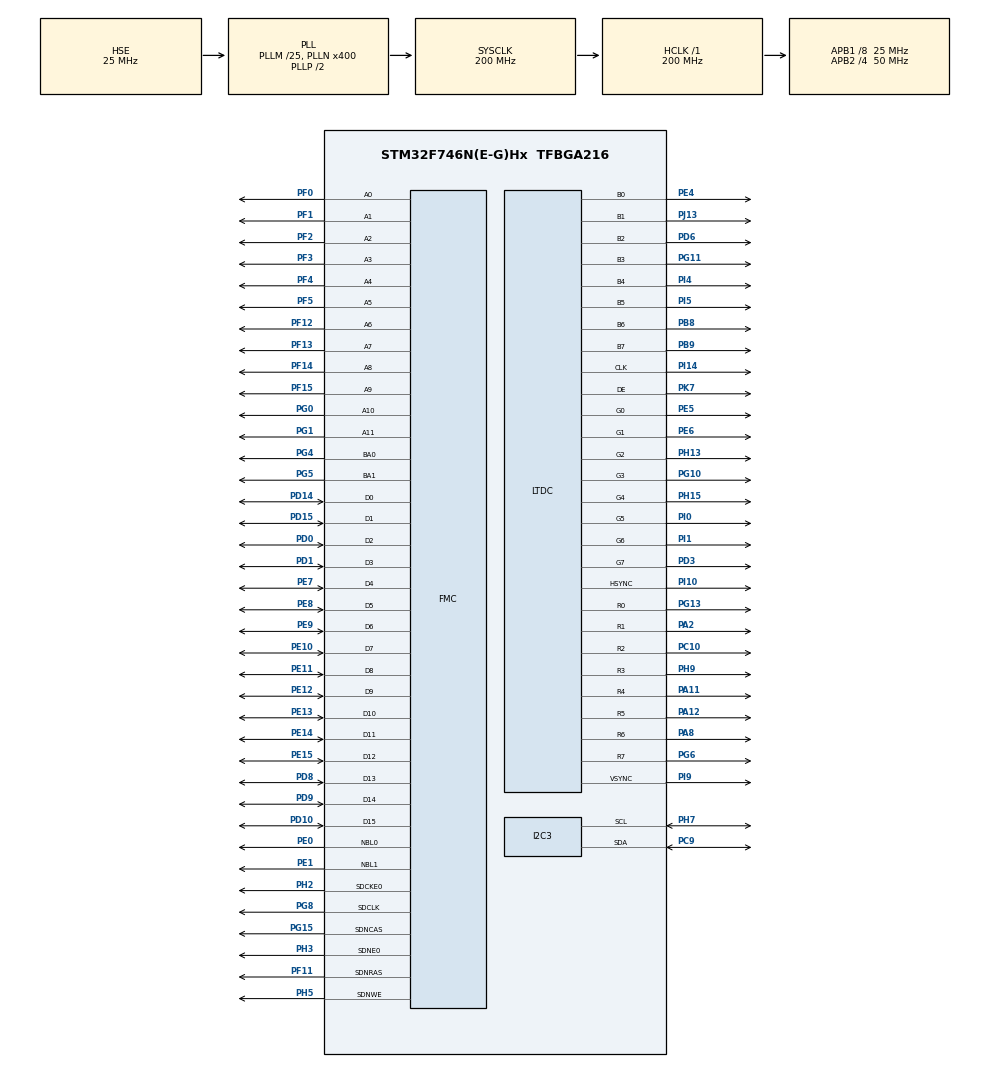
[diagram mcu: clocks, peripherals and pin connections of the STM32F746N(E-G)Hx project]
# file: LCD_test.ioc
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FMC.CASLatency1=FMC_SDRAM_CAS_LATENCY_2
FMC.ExitSelfRefreshDelay1=7
FMC.LoadToActiveDelay1=2
FMC.RCDDelay1=2
FMC.RPDelay1=2
FMC.RPDelay2=2
FMC.ReadBurst1=FMC_SDRAM_RBURST_ENABLE
FMC.ReadBurst2=FMC_SDRAM_RBURST_ENABLE
FMC.RowBitsNumber1=FMC_SDRAM_ROW_BITS_NUM_12
FMC.RowCycleDelay1=6
FMC.RowCycleDelay2=6
FMC.SDClockPeriod1=FMC_SDRAM_CLOCK_PERIOD_2
FMC.SDClockPeriod2=FMC_SDRAM_CLOCK_PERIOD_2
FMC.SelfRefreshTime1=4
FMC.WriteRecoveryTime1=2
I2C3.OwnAddress=112
I2C3.Timing=0x00606092
LTDC.ActiveH=272
LTDC.ActiveW=480
LTDC.HBP=43
LTDC.HFP=8
LTDC.HSync=1
LTDC.VBP=12
LTDC.VFP=4
LTDC.VSync=1
Mcu.Family=STM32F7
Mcu.Name=STM32F746N(E-G)Hx
Mcu.Package=TFBGA216
NVIC.PriorityGroup=NVIC_PRIORITYGROUP_4
PA11.Mode=RGB888
PA11.Signal=LTDC_R4
PA12.Mode=RGB888
PA12.Signal=LTDC_R5
PA2.Mode=RGB888
PA2.Signal=LTDC_R1
PA8.Mode=RGB888
PA8.Signal=LTDC_R6
PB8.Mode=RGB888
PB8.Signal=LTDC_B6
PB9.Mode=RGB888
PB9.Signal=LTDC_B7
PC10.Mode=RGB888
PC10.Signal=LTDC_R2
PC14/OSC32_IN.Mode=LSE-External-Oscillator
PC14/OSC32_IN.Signal=RCC_OSC32_IN
PC15/OSC32_OUT.Mode=LSE-External-Oscillator
PC15/OSC32_OUT.Signal=RCC_OSC32_OUT
PC9.Mode=I2C
PC9.Signal=I2C3_SDA
PD0.Signal=FMC_D2_DA2
PD1.Signal=FMC_D3_DA3
PD10.Signal=FMC_D15_DA15
PD14.Signal=FMC_D0_DA0
PD15.Signal=FMC_D1_DA1
PD3.Mode=RGB888
PD3.Signal=LTDC_G7
PD6.Mode=RGB888
PD6.Signal=LTDC_B2
PD8.Signal=FMC_D13_DA13
PD9.Signal=FMC_D14_DA14
PE0.Signal=FMC_NBL0
PE1.Signal=FMC_NBL1
PE10.Signal=FMC_D7_DA7
PE11.Signal=FMC_D8_DA8
PE12.Signal=FMC_D9_DA9
PE13.Signal=FMC_D10_DA10
PE14.Signal=FMC_D11_DA11
PE15.Signal=FMC_D12_DA12
PE4.Mode=RGB888
PE4.Signal=LTDC_B0
PE5.Mode=RGB888
PE5.Signal=LTDC_G0
PE6.Mode=RGB888
PE6.Signal=LTDC_G1
PE7.Signal=FMC_D4_DA4
PE8.Signal=FMC_D5_DA5
PE9.Signal=FMC_D6_DA6
PF0.Signal=FMC_A0
PF1.Signal=FMC_A1
PF11.Signal=FMC_SDNRAS
PF12.Signal=FMC_A6
PF13.Signal=FMC_A7
PF14.Signal=FMC_A8
PF15.Signal=FMC_A9
PF2.Signal=FMC_A2
PF3.Signal=FMC_A3
PF4.Signal=FMC_A4
PF5.Signal=FMC_A5
PG0.Signal=FMC_A10
PG1.Signal=FMC_A11
PG10.Mode=RGB888
PG10.Signal=LTDC_G3
PG11.Mode=RGB888
PG11.Signal=LTDC_B3
PG13.Mode=RGB888
PG13.Signal=LTDC_R0
PG15.Signal=FMC_SDNCAS
PG4.Signal=FMC_A14_BA0
PG5.Signal=FMC_A15_BA1
PG6.Mode=RGB888
PG6.Signal=LTDC_R7
PG8.Signal=FMC_SDCLK
PH0/OSC_IN.Mode=HSE-External-Oscillator
PH0/OSC_IN.Signal=RCC_OSC_IN
PH1/OSC_OUT.Mode=HSE-External-Oscillator
PH1/OSC_OUT.Signal=RCC_OSC_OUT
PH13.Mode=RGB888
PH13.Signal=LTDC_G2
PH15.Mode=RGB888
PH15.Signal=LTDC_G4
PH2.Mode=SdramChipSelect1_1
PH2.Signal=FMC_SDCKE0
PH3.Mode=SdramChipSelect1_1
PH3.Signal=FMC_SDNE0
PH5.Signal=FMC_SDNWE
PH7.Mode=I2C
PH7.Signal=I2C3_SCL
PH9.Mode=RGB888
PH9.Signal=LTDC_R3
PI0.Mode=RGB888
PI0.Signal=LTDC_G5
PI1.Mode=RGB888
PI1.Signal=LTDC_G6
PI10.Mode=RGB888
PI10.Signal=LTDC_HSYNC
PI14.Mode=RGB888
PI14.Signal=LTDC_CLK
PI4.Mode=RGB888
PI4.Signal=LTDC_B4
PI5.Mode=RGB888
PI5.Signal=LTDC_B5
PI9.Mode=RGB888
PI9.Signal=LTDC_VSYNC
PJ13.Mode=RGB888
PJ13.Signal=LTDC_B1
PK7.Mode=RGB888
PK7.Signal=LTDC_DE
ProjectManager.HeapSize=0x200
ProjectManager.StackSize=0x400
ProjectManager.TargetToolchain=SW4STM32
RCC.AHBFreq_Value=200000000
RCC.APB1CLKDivider=RCC_HCLK_DIV8
RCC.APB1Freq_Value=25000000
RCC.APB1TimFreq_Value=50000000
RCC.APB2CLKDivider=RCC_HCLK_DIV4
RCC.APB2Freq_Value=50000000
RCC.APB2TimFreq_Value=100000000
RCC.CortexFreq_Value=200000000
RCC.HCLKFreq_Value=200000000
RCC.HSE_VALUE=25000000
RCC.HSI_VALUE=16000000
RCC.PLLI2SN=100
RCC.PLLM=25
RCC.PLLN=400
RCC.PLLSAIR=5
RCC.PLLSAIRDiv=RCC_PLLSAIDIVR_4
RCC.PLLSourceVirtual=RCC_PLLSOURCE_HSE
RCC.SYSCLKFreq_VALUE=200000000
RCC.SYSCLKSource=RCC_SYSCLKSOURCE_PLLCLK
RCC.USBFreq_Value=200000000
RCC.VCOOutputFreq_Value=400000000
SH.FMC_A0.0=FMC_A0,12b-sda1
SH.FMC_A1.0=FMC_A1,12b-sda1
SH.FMC_A10.0=FMC_A10,12b-sda1
SH.FMC_A11.0=FMC_A11,12b-sda1
SH.FMC_A14_BA0.0=FMC_BA0,FourSdramBanks1
SH.FMC_A15_BA1.0=FMC_BA1,FourSdramBanks1
SH.FMC_A2.0=FMC_A2,12b-sda1
SH.FMC_A3.0=FMC_A3,12b-sda1
SH.FMC_A4.0=FMC_A4,12b-sda1
SH.FMC_A5.0=FMC_A5,12b-sda1
SH.FMC_A6.0=FMC_A6,12b-sda1
SH.FMC_A7.0=FMC_A7,12b-sda1
SH.FMC_A8.0=FMC_A8,12b-sda1
SH.FMC_A9.0=FMC_A9,12b-sda1
SH.FMC_D0_DA0.0=FMC_D0,sd-16b-d1
SH.FMC_D10_DA10.0=FMC_D10,sd-16b-d1
SH.FMC_D11_DA11.0=FMC_D11,sd-16b-d1
SH.FMC_D12_DA12.0=FMC_D12,sd-16b-d1
SH.FMC_D13_DA13.0=FMC_D13,sd-16b-d1
SH.FMC_D14_DA14.0=FMC_D14,sd-16b-d1
SH.FMC_D15_DA15.0=FMC_D15,sd-16b-d1
SH.FMC_D1_DA1.0=FMC_D1,sd-16b-d1
SH.FMC_D2_DA2.0=FMC_D2,sd-16b-d1
SH.FMC_D3_DA3.0=FMC_D3,sd-16b-d1
SH.FMC_D4_DA4.0=FMC_D4,sd-16b-d1
SH.FMC_D5_DA5.0=FMC_D5,sd-16b-d1
SH.FMC_D6_DA6.0=FMC_D6,sd-16b-d1
SH.FMC_D7_DA7.0=FMC_D7,sd-16b-d1
SH.FMC_D8_DA8.0=FMC_D8,sd-16b-d1
SH.FMC_D9_DA9.0=FMC_D9,sd-16b-d1
SH.FMC_NBL0.0=FMC_NBL0,Sd2ByteEnable1
SH.FMC_NBL1.0=FMC_NBL1,Sd2ByteEnable1
SH.FMC_SDCLK.0=FMC_SDCLK,12b-sda1
SH.FMC_SDNCAS.0=FMC_SDNCAS,12b-sda1
SH.FMC_SDNRAS.0=FMC_SDNRAS,12b-sda1
SH.FMC_SDNWE.0=FMC_SDNWE,12b-sda1
VP_DMA2D_VS_DMA2D.Mode=DMA2D_Activate
board=STM32F746G-DISCO

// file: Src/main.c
/**
  ******************************************************************************
  * File Name          : main.c
  * Description        : Main program body
  ******************************************************************************
  *
  * COPYRIGHT(c) 2016 STMicroelectronics
  *
  * Redistribution and use in source and binary forms, with or without modification,
  * are permitted provided that the following conditions are met:
  *   1. Redistributions of source code must retain the above copyright notice,
  *      this list of conditions and the following disclaimer.
  *   2. Redistributions in binary form must reproduce the above copyright notice,
  *      this list of conditions and the following disclaimer in the documentation
  *      and/or other materials provided with the distribution.
  *   3. Neither the name of STMicroelectronics nor the names of its contributors
  *      may be used to endorse or promote products derived from this software
  *      without specific prior written permission.
  *
  * THIS SOFTWARE IS PROVIDED BY THE COPYRIGHT HOLDERS AND CONTRIBUTORS "AS IS"
  * AND ANY EXPRESS OR IMPLIED WARRANTIES, INCLUDING, BUT NOT LIMITED TO, THE
  * IMPLIED WARRANTIES OF MERCHANTABILITY AND FITNESS FOR A PARTICULAR PURPOSE ARE
  * DISCLAIMED. IN NO EVENT SHALL THE COPYRIGHT HOLDER OR CONTRIBUTORS BE LIABLE
  * FOR ANY DIRECT, INDIRECT, INCIDENTAL, SPECIAL, EXEMPLARY, OR CONSEQUENTIAL
  * DAMAGES (INCLUDING, BUT NOT LIMITED TO, PROCUREMENT OF SUBSTITUTE GOODS OR
  * SERVICES; LOSS OF USE, DATA, OR PROFITS; OR BUSINESS INTERRUPTION) HOWEVER
  * CAUSED AND ON ANY THEORY OF LIABILITY, WHETHER IN CONTRACT, STRICT LIABILITY,
  * OR TORT (INCLUDING NEGLIGENCE OR OTHERWISE) ARISING IN ANY WAY OUT OF THE USE
  * OF THIS SOFTWARE, EVEN IF ADVISED OF THE POSSIBILITY OF SUCH DAMAGE.
  *
  ******************************************************************************
  */
#include "stm32f7xx_hal.h"

/* USER CODE BEGIN Includes */
#include "stm32746g_discovery.h"
#include "stm32746g_discovery_lcd.h"
#include "stm32746g_discovery_sdram.h"
#include "stm32746g_discovery_ts.h"
/* USER CODE END Includes */

DMA2D_HandleTypeDef hdma2d;

I2C_HandleTypeDef hi2c3;

LTDC_HandleTypeDef hltdc;

SDRAM_HandleTypeDef hsdram1;

/* USER CODE BEGIN PV */
/* Private variables ---------------------------------------------------------*/

/* USER CODE END PV */

void SystemClock_Config(void);
void Error_Handler(void);
static void MX_GPIO_Init(void);
static void MX_DMA2D_Init(void);
static void MX_FMC_Init(void);
static void MX_I2C3_Init(void);
static void MX_LTDC_Init(void);
//static void SystemClock_Config(void);

/* USER CODE BEGIN PFP */
/* Private function prototypes -----------------------------------------------*/

/* USER CODE END PFP */

int main(void)
{

  /* USER CODE BEGIN 1 */
	TS_StateTypeDef buffer;
  /* USER CODE END 1 */

  /* MCU Configuration----------------------------------------------------------*/

  /* Reset of all peripherals, Initializes the Flash interface and the Systick. */
  HAL_Init();

  /* Configure the system clock */
  SystemClock_Config();

  /* Initialize all configured peripherals */
  MX_GPIO_Init();
  MX_DMA2D_Init();
  MX_FMC_Init();
  MX_I2C3_Init();
  MX_LTDC_Init();
  //SystemClock_Config();

  /* USER CODE BEGIN 2 */
    /* LCD Initialization */
    BSP_LCD_Init();
    BSP_LCD_LayerDefaultInit(0, LCD_FB_START_ADDRESS);
    /* Enable the LCD */
    BSP_LCD_DisplayOn();
    /* Select the LCD Background Layer  */
    BSP_LCD_SelectLayer(0);
    /* Clear the Background Layer */
    BSP_LCD_Clear(LCD_COLOR_BLACK);
    /* Some sign */
    BSP_LCD_SetTextColor(LCD_COLOR_RED);
    BSP_LCD_SetFont(&Font12);
    if(BSP_TS_Init(480,272) == TS_OK){
  	  BSP_LCD_DisplayStringAt(0, 0, (uint8_t*) "Display & TS is working", CENTER_MODE);
    }
    else
    {
  	  BSP_LCD_DisplayStringAt(0, 0, (uint8_t*) "TS is not working", CENTER_MODE);
    }

  /* USER CODE END 2 */

  /* Infinite loop */
    while (1)
    {

  /* USER CODE BEGIN 3 */
  	  BSP_TS_GetState(&buffer);
  	  if(buffer.touchDetected > 0){
  		  BSP_LCD_DisplayStringAt(0, 16, (uint8_t*) "Haal uw vinger weg", CENTER_MODE);
  	  }else{
  		  BSP_LCD_DisplayStringAt(0, 16, (uint8_t*) "plaats uw vinger op het scherm", CENTER_MODE);
  	  }
    }
  /* USER CODE END 3 */

}

/** System Clock Configuration
*/
void SystemClock_Config(void)
{

  RCC_OscInitTypeDef RCC_OscInitStruct;
  RCC_ClkInitTypeDef RCC_ClkInitStruct;
  RCC_PeriphCLKInitTypeDef PeriphClkInitStruct;

  __HAL_RCC_PWR_CLK_ENABLE();

  __HAL_PWR_VOLTAGESCALING_CONFIG(PWR_REGULATOR_VOLTAGE_SCALE1);

  RCC_OscInitStruct.OscillatorType = RCC_OSCILLATORTYPE_HSE;
  RCC_OscInitStruct.HSEState = RCC_HSE_ON;
  RCC_OscInitStruct.PLL.PLLState = RCC_PLL_ON;
  RCC_OscInitStruct.PLL.PLLSource = RCC_PLLSOURCE_HSE;
  RCC_OscInitStruct.PLL.PLLM = 25;
  RCC_OscInitStruct.PLL.PLLN = 400;
  RCC_OscInitStruct.PLL.PLLP = RCC_PLLP_DIV2;
  RCC_OscInitStruct.PLL.PLLQ = 2;
  if (HAL_RCC_OscConfig(&RCC_OscInitStruct) != HAL_OK)
  {
    Error_Handler();
  }

  if (HAL_PWREx_EnableOverDrive() != HAL_OK)
  {
    Error_Handler();
  }

  RCC_ClkInitStruct.ClockType = RCC_CLOCKTYPE_HCLK|RCC_CLOCKTYPE_SYSCLK
                              |RCC_CLOCKTYPE_PCLK1|RCC_CLOCKTYPE_PCLK2;
  RCC_ClkInitStruct.SYSCLKSource = RCC_SYSCLKSOURCE_PLLCLK;
  RCC_ClkInitStruct.AHBCLKDivider = RCC_SYSCLK_DIV1;
  RCC_ClkInitStruct.APB1CLKDivider = RCC_HCLK_DIV8;
  RCC_ClkInitStruct.APB2CLKDivider = RCC_HCLK_DIV4;
  if (HAL_RCC_ClockConfig(&RCC_ClkInitStruct, FLASH_LATENCY_6) != HAL_OK)
  {
    Error_Handler();
  }

  PeriphClkInitStruct.PeriphClockSelection = RCC_PERIPHCLK_LTDC|RCC_PERIPHCLK_I2C3;
  PeriphClkInitStruct.PLLSAI.PLLSAIN = 192;
  PeriphClkInitStruct.PLLSAI.PLLSAIR = 5;
  PeriphClkInitStruct.PLLSAI.PLLSAIQ = 2;
  PeriphClkInitStruct.PLLSAI.PLLSAIP = RCC_PLLSAIP_DIV2;
  PeriphClkInitStruct.PLLSAIDivQ = 1;
  PeriphClkInitStruct.PLLSAIDivR = RCC_PLLSAIDIVR_4;
  PeriphClkInitStruct.I2c3ClockSelection = RCC_I2C3CLKSOURCE_PCLK1;
  if (HAL_RCCEx_PeriphCLKConfig(&PeriphClkInitStruct) != HAL_OK)
  {
    Error_Handler();
  }

  HAL_SYSTICK_Config(HAL_RCC_GetHCLKFreq()/1000);

  HAL_SYSTICK_CLKSourceConfig(SYSTICK_CLKSOURCE_HCLK);

  /* SysTick_IRQn interrupt configuration */
  HAL_NVIC_SetPriority(SysTick_IRQn, 0, 0);
}

/* DMA2D init function */
static void MX_DMA2D_Init(void)
{

  hdma2d.Instance = DMA2D;
  hdma2d.Init.Mode = DMA2D_M2M;
  hdma2d.Init.ColorMode = DMA2D_OUTPUT_ARGB8888;
  hdma2d.Init.OutputOffset = 0;
  hdma2d.LayerCfg[1].InputOffset = 0;
  hdma2d.LayerCfg[1].InputColorMode = DMA2D_INPUT_ARGB8888;
  hdma2d.LayerCfg[1].AlphaMode = DMA2D_NO_MODIF_ALPHA;
  hdma2d.LayerCfg[1].InputAlpha = 0;
  if (HAL_DMA2D_Init(&hdma2d) != HAL_OK)
  {
    Error_Handler();
  }

  if (HAL_DMA2D_ConfigLayer(&hdma2d, 1) != HAL_OK)
  {
    Error_Handler();
  }

}

/* I2C3 init function */
static void MX_I2C3_Init(void)
{

  hi2c3.Instance = I2C3;
  hi2c3.Init.Timing = 0x00606092;
  hi2c3.Init.OwnAddress1 = 224;
  hi2c3.Init.AddressingMode = I2C_ADDRESSINGMODE_7BIT;
  hi2c3.Init.DualAddressMode = I2C_DUALADDRESS_DISABLE;
  hi2c3.Init.OwnAddress2 = 0;
  hi2c3.Init.OwnAddress2Masks = I2C_OA2_NOMASK;
  hi2c3.Init.GeneralCallMode = I2C_GENERALCALL_DISABLE;
  hi2c3.Init.NoStretchMode = I2C_NOSTRETCH_DISABLE;
  if (HAL_I2C_Init(&hi2c3) != HAL_OK)
  {
    Error_Handler();
  }

    /**Configure Analogue filter
    */
  if (HAL_I2CEx_ConfigAnalogFilter(&hi2c3, I2C_ANALOGFILTER_ENABLE) != HAL_OK)
  {
    Error_Handler();
  }

}

/* LTDC init function */
static void MX_LTDC_Init(void)
{

  LTDC_LayerCfgTypeDef pLayerCfg;
  LTDC_LayerCfgTypeDef pLayerCfg1;

  hltdc.Instance = LTDC;
  hltdc.Init.HSPolarity = LTDC_HSPOLARITY_AL;
  hltdc.Init.VSPolarity = LTDC_VSPOLARITY_AL;
  hltdc.Init.DEPolarity = LTDC_DEPOLARITY_AL;
  hltdc.Init.PCPolarity = LTDC_PCPOLARITY_IPC;
  hltdc.Init.HorizontalSync = 0;
  hltdc.Init.VerticalSync = 0;
  hltdc.Init.AccumulatedHBP = 43;
  hltdc.Init.AccumulatedVBP = 12;
  hltdc.Init.AccumulatedActiveW = 523;
  hltdc.Init.AccumulatedActiveH = 284;
  hltdc.Init.TotalWidth = 531;
  hltdc.Init.TotalHeigh = 288;
  hltdc.Init.Backcolor.Blue = 0;
  hltdc.Init.Backcolor.Green = 0;
  hltdc.Init.Backcolor.Red = 0;
  if (HAL_LTDC_Init(&hltdc) != HAL_OK)
  {
    Error_Handler();
  }

  pLayerCfg.WindowX0 = 0;
  pLayerCfg.WindowX1 = 0;
  pLayerCfg.WindowY0 = 0;
  pLayerCfg.WindowY1 = 0;
  pLayerCfg.PixelFormat = LTDC_PIXEL_FORMAT_ARGB8888;
  pLayerCfg.Alpha = 0;
  pLayerCfg.Alpha0 = 0;
  pLayerCfg.BlendingFactor1 = LTDC_BLENDING_FACTOR1_CA;
  pLayerCfg.BlendingFactor2 = LTDC_BLENDING_FACTOR2_CA;
  pLayerCfg.FBStartAdress = 0;
  pLayerCfg.ImageWidth = 0;
  pLayerCfg.ImageHeight = 0;
  pLayerCfg.Backcolor.Blue = 0;
  pLayerCfg.Backcolor.Green = 0;
  pLayerCfg.Backcolor.Red = 0;
  if (HAL_LTDC_ConfigLayer(&hltdc, &pLayerCfg, 0) != HAL_OK)
  {
    Error_Handler();
  }

  pLayerCfg1.WindowX0 = 0;
  pLayerCfg1.WindowX1 = 0;
  pLayerCfg1.WindowY0 = 0;
  pLayerCfg1.WindowY1 = 0;
  pLayerCfg1.PixelFormat = LTDC_PIXEL_FORMAT_ARGB8888;
  pLayerCfg1.Alpha = 0;
  pLayerCfg1.Alpha0 = 0;
  pLayerCfg1.BlendingFactor1 = LTDC_BLENDING_FACTOR1_CA;
  pLayerCfg1.BlendingFactor2 = LTDC_BLENDING_FACTOR2_CA;
  pLayerCfg1.FBStartAdress = 0;
  pLayerCfg1.ImageWidth = 0;
  pLayerCfg1.ImageHeight = 0;
  pLayerCfg1.Backcolor.Blue = 0;
  pLayerCfg1.Backcolor.Green = 0;
  pLayerCfg1.Backcolor.Red = 0;
  if (HAL_LTDC_ConfigLayer(&hltdc, &pLayerCfg1, 1) != HAL_OK)
  {
    Error_Handler();
  }

}
/* FMC initialization function */
static void MX_FMC_Init(void)
{
  FMC_SDRAM_TimingTypeDef SdramTiming;

  /** Perform the SDRAM1 memory initialization sequence
  */
  hsdram1.Instance = FMC_SDRAM_DEVICE;
  /* hsdram1.Init */
  hsdram1.Init.SDBank = FMC_SDRAM_BANK1;
  hsdram1.Init.ColumnBitsNumber = FMC_SDRAM_COLUMN_BITS_NUM_8;
  hsdram1.Init.RowBitsNumber = FMC_SDRAM_ROW_BITS_NUM_12;
  hsdram1.Init.MemoryDataWidth = FMC_SDRAM_MEM_BUS_WIDTH_16;
  hsdram1.Init.InternalBankNumber = FMC_SDRAM_INTERN_BANKS_NUM_4;
  hsdram1.Init.CASLatency = FMC_SDRAM_CAS_LATENCY_2;
  hsdram1.Init.WriteProtection = FMC_SDRAM_WRITE_PROTECTION_DISABLE;
  hsdram1.Init.SDClockPeriod = FMC_SDRAM_CLOCK_PERIOD_2;
  hsdram1.Init.ReadBurst = FMC_SDRAM_RBURST_ENABLE;
  hsdram1.Init.ReadPipeDelay = FMC_SDRAM_RPIPE_DELAY_0;
  /* SdramTiming */
  SdramTiming.LoadToActiveDelay = 2;
  SdramTiming.ExitSelfRefreshDelay = 7;
  SdramTiming.SelfRefreshTime = 4;
  SdramTiming.RowCycleDelay = 6;
  SdramTiming.WriteRecoveryTime = 2;
  SdramTiming.RPDelay = 2;
  SdramTiming.RCDDelay = 2;

  if (HAL_SDRAM_Init(&hsdram1, &SdramTiming) != HAL_OK)
  {
    Error_Handler();
  }

}

/** Configure pins as
        * Analog
        * Input
        * Output
        * EVENT_OUT
        * EXTI
*/
static void MX_GPIO_Init(void)
{

  /* GPIO Ports Clock Enable */
  __HAL_RCC_GPIOE_CLK_ENABLE();
  __HAL_RCC_GPIOB_CLK_ENABLE();
  __HAL_RCC_GPIOG_CLK_ENABLE();
  __HAL_RCC_GPIOJ_CLK_ENABLE();
  __HAL_RCC_GPIOD_CLK_ENABLE();
  __HAL_RCC_GPIOC_CLK_ENABLE();
  __HAL_RCC_GPIOA_CLK_ENABLE();
  __HAL_RCC_GPIOI_CLK_ENABLE();
  __HAL_RCC_GPIOK_CLK_ENABLE();
  __HAL_RCC_GPIOF_CLK_ENABLE();
  __HAL_RCC_GPIOH_CLK_ENABLE();

}

void Error_Handler(void)
{
  while(1)
  {
  }
}

/************************ (C) COPYRIGHT STMicroelectronics *****END OF FILE****/
